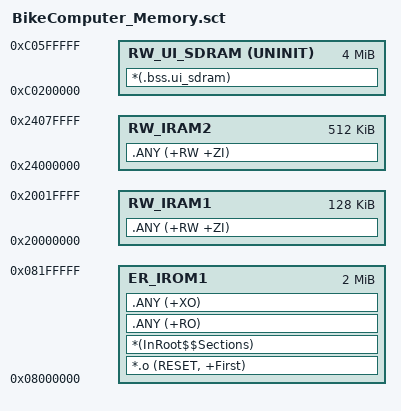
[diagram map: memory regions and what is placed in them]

;============================================================
; STM32H743 正式内存分配文件
;
; 文件：BikeComputer_Memory.sct
;
; Flash：2 MiB
; DTCM：128 KiB
; AXI SRAM：512 KiB
; SDRAM：32 MiB
;
; 当前阶段：
; 保留已有的内部存储器布局，
; 增加 UI 专用外部 SDRAM 区域。
;============================================================

LR_IROM1 0x08000000 0x00200000
{

    ;--------------------------------------------------------
    ; STM32 内部 Flash
    ; 当前暂不调整 Bootloader/Application 分区。
    ;--------------------------------------------------------
    ER_IROM1 0x08000000 0x00200000
    {
        *.o (RESET, +First)
        *(InRoot$$Sections)
        .ANY (+RO)
        .ANY (+XO)
    }

    ;--------------------------------------------------------
    ; UI 大型零初始化变量专用区域
    ;
    ; 地址：0xC0200000
    ; 最大容量：4 MiB
    ;
    ; UNINIT：
    ; 启动时不由 C 运行库自动清零。
    ;
    ; 必须在 FMC/SDRAM 初始化完成之后，
    ; 由应用程序显式初始化。
    ;--------------------------------------------------------
    RW_UI_SDRAM 0xC0200000 UNINIT 0x00400000
    {
        *(.bss.ui_sdram)
    }

    ;--------------------------------------------------------
    ; STM32 内部 DTCM：128 KiB
    ;--------------------------------------------------------
    RW_IRAM1 0x20000000 0x00020000
    {
        .ANY (+RW +ZI)
    }

    ;--------------------------------------------------------
    ; STM32 内部 AXI SRAM：512 KiB
    ;--------------------------------------------------------
    RW_IRAM2 0x24000000 0x00080000
    {
        .ANY (+RW +ZI)
    }
}
